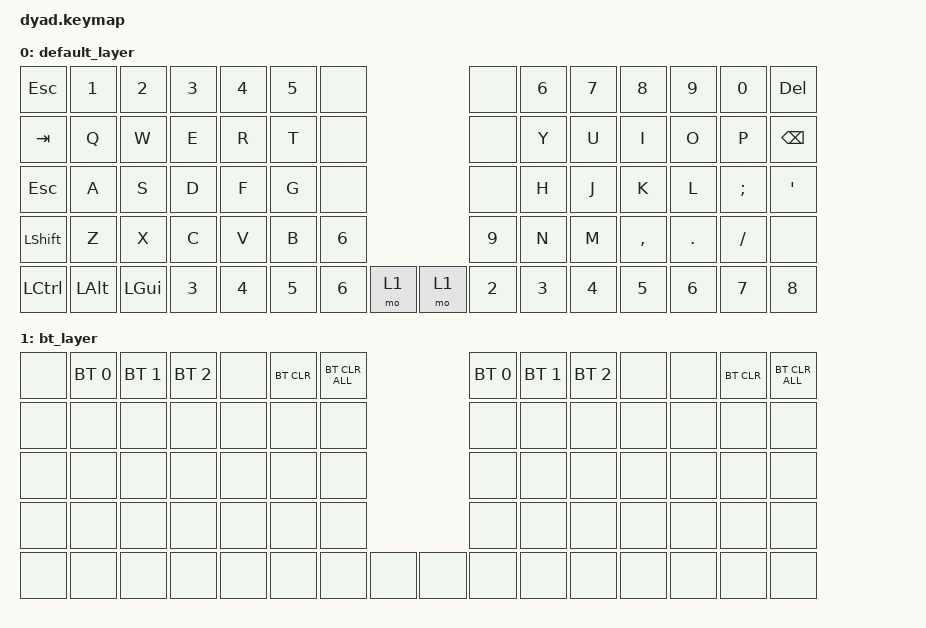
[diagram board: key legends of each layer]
#include <behaviors.dtsi>
#include <dt-bindings/zmk/keys.h>
#include <dt-bindings/zmk/bt.h>

/ {
    keymap {
        compatible = "zmk,keymap";

        default_layer {
            bindings = <
&kp ESC     &kp N1      &kp N2      &kp N3      &kp N4      &kp N5      &none                               &none       &kp N6      &kp N7      &kp N8      &kp N9      &kp N0      &kp DEL
&kp TAB     &kp Q       &kp W       &kp E       &kp R       &kp T       &none                               &none       &kp Y       &kp U       &kp I       &kp O       &kp P       &kp BSPC
&kp ESC     &kp A       &kp S       &kp D       &kp F       &kp G       &none                               &none       &kp H       &kp J       &kp K       &kp L       &kp SEMI    &kp SQT
&kp LSHFT   &kp Z       &kp X       &kp C       &kp V       &kp B       &kp N6                              &kp N9      &kp N       &kp M       &kp COMMA   &kp DOT     &kp SLASH   &none
&kp LCTRL   &kp LALT    &kp LGUI    &kp N3      &kp N4      &kp N5      &kp N6      &mo 1        &mo 1      &kp N2      &kp N3      &kp N4      &kp N5      &kp N6      &kp N7      &kp N8
            >;
        };

        bt_layer {
            bindings = <
&none       &bt BT_SEL 0&bt BT_SEL 1&bt BT_SEL 2&none       &bt BT_CLR  &bt BT_CLR_ALL                      &bt BT_SEL 0&bt BT_SEL 1&bt BT_SEL 2&none       &none       &bt BT_CLR  &bt BT_CLR_ALL
&none       &none       &none       &none       &none       &none       &none                               &none       &none       &none       &none       &none       &none       &none
&none       &none       &none       &none       &none       &none       &none                               &none       &none       &none       &none       &none       &none       &none
&none       &none       &none       &none       &none       &none       &none                               &none       &none       &none       &none       &none       &none       &none
&none       &none       &none       &none       &none       &none       &none       &none       &none       &none       &none       &none       &none       &none       &none       &none
            >;
        };
    };
};

